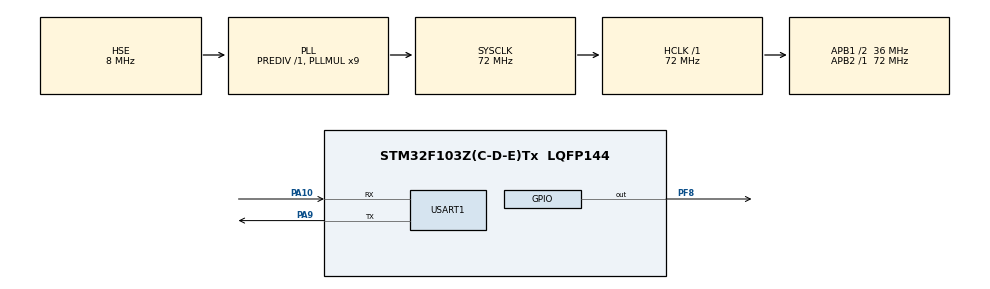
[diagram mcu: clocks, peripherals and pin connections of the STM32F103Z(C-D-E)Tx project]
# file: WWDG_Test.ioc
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Mcu.Family=STM32F1
Mcu.Name=STM32F103Z(C-D-E)Tx
Mcu.Package=LQFP144
NVIC.PriorityGroup=NVIC_PRIORITYGROUP_4
NVIC.WWDG_IRQn=true\:0\:0\:false\:false\:true\:true\:true\:true
OSC_IN.Mode=HSE-External-Oscillator
OSC_IN.Signal=RCC_OSC_IN
OSC_OUT.Mode=HSE-External-Oscillator
OSC_OUT.Signal=RCC_OSC_OUT
PA10.Mode=Asynchronous
PA10.Signal=USART1_RX
PA13.Mode=Serial_Wire
PA13.Signal=SYS_JTMS-SWDIO
PA14.Mode=Serial_Wire
PA14.Signal=SYS_JTCK-SWCLK
PA9.Mode=Asynchronous
PA9.Signal=USART1_TX
PF8.PinState=GPIO_PIN_SET
PF8.Signal=GPIO_Output
ProjectManager.HeapSize=0x200
ProjectManager.StackSize=0x400
ProjectManager.TargetToolchain=MDK-ARM V5.32
RCC.AHBFreq_Value=72000000
RCC.APB1CLKDivider=RCC_HCLK_DIV2
RCC.APB1Freq_Value=36000000
RCC.APB1TimFreq_Value=72000000
RCC.APB2Freq_Value=72000000
RCC.APB2TimFreq_Value=72000000
RCC.HCLKFreq_Value=72000000
RCC.PLLMUL=RCC_PLL_MUL9
RCC.PLLSourceVirtual=RCC_PLLSOURCE_HSE
RCC.SYSCLKFreq_VALUE=72000000
RCC.SYSCLKSource=RCC_SYSCLKSOURCE_PLLCLK
RCC.USBFreq_Value=72000000
USART1.Parity=PARITY_ODD
USART1.VirtualMode=VM_ASYNC
USART1.WordLength=WORDLENGTH_9B
VP_WWDG_VS_WWDG.Mode=WWDG_Activate
WWDG.Counter=127
WWDG.EWIMode=WWDG_EWI_ENABLE
WWDG.Prescaler=WWDG_PRESCALER_8
WWDG.Window=96
board=custom

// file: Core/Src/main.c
/* USER CODE BEGIN Header */
/**
 ******************************************************************************
 * @file           : main.c
 * @brief          : Main program body
 ******************************************************************************
 * @attention
 *
 * Copyright (c) 2026 STMicroelectronics.
 * All rights reserved.
 *
 * This software is licensed under terms that can be found in the LICENSE file
 * in the root directory of this software component.
 * If no LICENSE file comes with this software, it is provided AS-IS.
 *
 ******************************************************************************
 */
/* USER CODE END Header */
#include "main.h"

/* USER CODE BEGIN Includes */
#include "BSP_Usart_Redir.h"
/* USER CODE END Includes */

UART_HandleTypeDef huart1;

WWDG_HandleTypeDef hwwdg;

void SystemClock_Config(void);
static void MX_GPIO_Init(void);
static void MX_USART1_UART_Init(void);
static void MX_WWDG_Init(void);

int main(void)
{

  /* MCU Configuration--------------------------------------------------------*/

  /* Reset of all peripherals, Initializes the Flash interface and the Systick. */
  HAL_Init();

  /* Configure the system clock */
  SystemClock_Config();

  /* Initialize all configured peripherals */
  HAL_Delay(1000);

  MX_GPIO_Init();
  MX_USART1_UART_Init();
  MX_WWDG_Init();
  /* USER CODE BEGIN 2 */
  BSP_Usart_Init(&huart1);

  printf(">> WWDG : 板子被重置!\n");
  /* USER CODE END 2 */

  /* Infinite loop */
  /* USER CODE BEGIN WHILE */
  while (1)
  {
    // 获取downcounter计数器的值
    printf(">> 喂狗前: WWDG Counter: %lu\n", hwwdg.Instance->CR & WWDG_CR_T);
    HAL_Delay(60); // 模拟某种任务的执行
    HAL_WWDG_Refresh(&hwwdg);
    printf(">> 喂狗后: WWDG Counter: %lu\n", hwwdg.Instance->CR & WWDG_CR_T);

    /* USER CODE END WHILE */

  }
}

void SystemClock_Config(void)
{
  RCC_OscInitTypeDef RCC_OscInitStruct = {0};
  RCC_ClkInitTypeDef RCC_ClkInitStruct = {0};

  /** Initializes the RCC Oscillators according to the specified parameters
  * in the RCC_OscInitTypeDef structure.
  */
  RCC_OscInitStruct.OscillatorType = RCC_OSCILLATORTYPE_HSE;
  RCC_OscInitStruct.HSEState = RCC_HSE_ON;
  RCC_OscInitStruct.HSEPredivValue = RCC_HSE_PREDIV_DIV1;
  RCC_OscInitStruct.HSIState = RCC_HSI_ON;
  RCC_OscInitStruct.PLL.PLLState = RCC_PLL_ON;
  RCC_OscInitStruct.PLL.PLLSource = RCC_PLLSOURCE_HSE;
  RCC_OscInitStruct.PLL.PLLMUL = RCC_PLL_MUL9;
  if (HAL_RCC_OscConfig(&RCC_OscInitStruct) != HAL_OK)
  {
    Error_Handler();
  }

  /** Initializes the CPU, AHB and APB buses clocks
  */
  RCC_ClkInitStruct.ClockType = RCC_CLOCKTYPE_HCLK|RCC_CLOCKTYPE_SYSCLK
                              |RCC_CLOCKTYPE_PCLK1|RCC_CLOCKTYPE_PCLK2;
  RCC_ClkInitStruct.SYSCLKSource = RCC_SYSCLKSOURCE_PLLCLK;
  RCC_ClkInitStruct.AHBCLKDivider = RCC_SYSCLK_DIV1;
  RCC_ClkInitStruct.APB1CLKDivider = RCC_HCLK_DIV2;
  RCC_ClkInitStruct.APB2CLKDivider = RCC_HCLK_DIV1;

  if (HAL_RCC_ClockConfig(&RCC_ClkInitStruct, FLASH_LATENCY_2) != HAL_OK)
  {
    Error_Handler();
  }
}

static void MX_USART1_UART_Init(void)
{

  huart1.Instance = USART1;
  huart1.Init.BaudRate = 115200;
  huart1.Init.WordLength = UART_WORDLENGTH_9B;
  huart1.Init.StopBits = UART_STOPBITS_1;
  huart1.Init.Parity = UART_PARITY_ODD;
  huart1.Init.Mode = UART_MODE_TX_RX;
  huart1.Init.HwFlowCtl = UART_HWCONTROL_NONE;
  huart1.Init.OverSampling = UART_OVERSAMPLING_16;
  if (HAL_UART_Init(&huart1) != HAL_OK)
  {
    Error_Handler();
  }

}

static void MX_WWDG_Init(void)
{

  hwwdg.Instance = WWDG;
  hwwdg.Init.Prescaler = WWDG_PRESCALER_8;
  hwwdg.Init.Window = 96;
  hwwdg.Init.Counter = 127;
  hwwdg.Init.EWIMode = WWDG_EWI_ENABLE;
  if (HAL_WWDG_Init(&hwwdg) != HAL_OK)
  {
    Error_Handler();
  }

}

static void MX_GPIO_Init(void)
{
  GPIO_InitTypeDef GPIO_InitStruct = {0};

  /* GPIO Ports Clock Enable */
  __HAL_RCC_GPIOF_CLK_ENABLE();
  __HAL_RCC_GPIOA_CLK_ENABLE();

  /*Configure GPIO pin Output Level */
  HAL_GPIO_WritePin(GPIOF, GPIO_PIN_8, GPIO_PIN_SET);

  /*Configure GPIO pin : PF8 */
  GPIO_InitStruct.Pin = GPIO_PIN_8;
  GPIO_InitStruct.Mode = GPIO_MODE_OUTPUT_PP;
  GPIO_InitStruct.Pull = GPIO_NOPULL;
  GPIO_InitStruct.Speed = GPIO_SPEED_FREQ_LOW;
  HAL_GPIO_Init(GPIOF, &GPIO_InitStruct);

}

/* USER CODE BEGIN 4 */
void HAL_WWDG_EarlyWakeupCallback(WWDG_HandleTypeDef *hwwdg_)
{
  if(&hwwdg == hwwdg_)
  {
    HAL_GPIO_WritePin(GPIOF, GPIO_PIN_8, GPIO_PIN_RESET);
  }
}
/* USER CODE END 4 */

void Error_Handler(void)
{
  __disable_irq();
  while (1)
  {
  }
}
